VERSION ""

NS_ :

BS_:

BU_: StWhlSensor Engine ESP

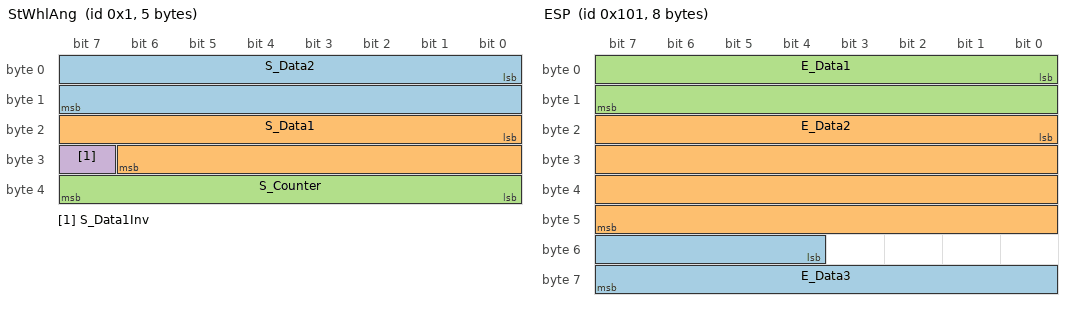
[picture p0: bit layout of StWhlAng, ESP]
BO_ 1 StWhlAng: 5 StWhlSensor
 SG_ S_Data2 : 0|16@1- (1,0) [0|0] "°"  ESP
 SG_ S_Data1 : 16|15@1- (0.04375,0) [-716.8|716.75625] "°/s"  ESP
 SG_ S_Counter : 32|8@1+ (1,0) [0|255] ""  ESP
 SG_ S_Data1Inv : 31|1@1+ (1,0) [0|0] ""  ESP

BO_ 514 Engine_2: 4 Engine
 SG_ E2_Data2 : 24|8@1+ (1,0) [0|170] ""  ESP
 SG_ E2_Data1 : 0|24@1+ (1,0) [0|16777215] ""  ESP

BO_ 513 Engine_1: 8 Engine
 SG_ E1_Info : 42|4@1+ (1,0) [0|0] ""  ESP
 SG_ E1_Data3 m1 : 20|4@1+ (0.25,0) [0|3.75] "rpm" Vector__XXX
 SG_ E1_MPlex M : 0|3@1+ (1,0) [0|7] ""  ESP
 SG_ E1_Data2 m1 : 8|12@1+ (1,0) [0|4095] "" Vector__XXX
 SG_ E1_Data1 m0 : 8|16@1+ (1,0) [0|65535] ""  ESP

BO_ 257 ESP: 8 ESP
 SG_ E_Data3 : 52|12@1- (0.035,0) [-71.68|71.645] "" Vector__XXX
 SG_ E_Data2 : 16|32@1- (1,0) [0|0] "" Vector__XXX
 SG_ E_Data1 : 0|16@1+ (1,0) [0|0] ""  Engine

CM_ SG_ 1 S_Data2 "Data 2";
CM_ SG_ 1 S_Data1 "Data 1";
CM_ SG_ 1 S_Counter "Msg Counter";
CM_ SG_ 514 E2_Data2 "Data 2";
CM_ SG_ 514 E2_Data1 "Data 1";
CM_ SG_ 513 E1_Data3 "Data 3";
CM_ SG_ 513 E1_MPlex "Multiplexer";
CM_ SG_ 513 E1_Data2 "Data 2";
CM_ SG_ 513 E1_Data1 "Data 1";
BA_DEF_ BO_  "GenMsgSendType" ENUM  "cyclic","spontaneous","cyclicIfActive","spontaneousWithDelay","cyclicAndSpontaneous","cyclicAndSpontaneousWithDelay","spontaneousWithRepetition","cyclicIfActiveAndSpontaneousWD";
BA_DEF_ BO_  "GenMsgNrOfRepetitions" INT 1 999999;
BA_DEF_ BO_  "GenMsgDelayTime" INT 1 1000;
BA_DEF_ BO_  "GenMsgCycleTime" INT 2 50000;
BA_DEF_DEF_  "GenMsgSendType" "spontaneous";
BA_DEF_DEF_  "GenMsgNrOfRepetitions" 1;
BA_DEF_DEF_  "GenMsgDelayTime" 1;
BA_DEF_DEF_  "GenMsgCycleTime" 100;
BA_ "GenMsgCycleTime" BO_ 1 50;
BA_ "GenMsgDelayTime" BO_ 1 4;
BA_ "GenMsgSendType" BO_ 1 0;
BA_ "GenMsgSendType" BO_ 514 0;
BA_ "GenMsgDelayTime" BO_ 514 7;
BA_ "GenMsgSendType" BO_ 513 0;
BA_ "GenMsgDelayTime" BO_ 513 5;
BA_ "GenMsgCycleTime" BO_ 513 20;
BA_ "GenMsgCycleTime" BO_ 257 10;
BA_ "GenMsgSendType" BO_ 257 0;
